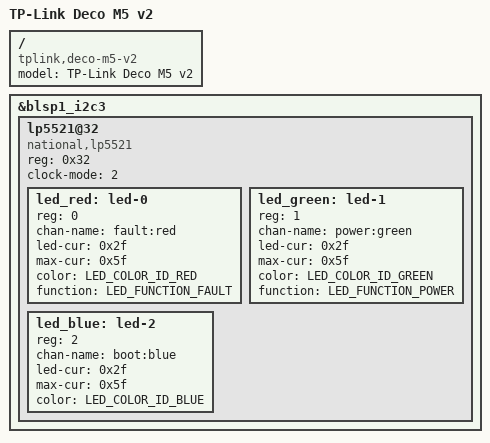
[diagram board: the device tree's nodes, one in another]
// SPDX-License-Identifier: ISC
// Copyright (c) 2015, The Linux Foundation. All rights reserved.
// Copyright (c) 2021, Frank Veltmans <veltmans.frank@gmail.com>

#include "qcom-ipq4019-deco-m5.dtsi"

/ {
	model = "TP-Link Deco M5 v2";
	compatible = "tplink,deco-m5-v2";
};

&blsp1_i2c3 {
	lp5521@32 {
		compatible = "national,lp5521";
		reg = <0x32>;
		clock-mode = /bits/ 8 <2>;

		led_red: led-0 {
			reg = <0>;
			chan-name = "fault:red";
			led-cur = /bits/ 8 <0x2f>;
			max-cur = /bits/ 8 <0x5f>;
			color = <LED_COLOR_ID_RED>;
			function = LED_FUNCTION_FAULT;
		};
		led_green: led-1 {
			reg = <1>;
			chan-name = "power:green";
			led-cur = /bits/ 8 <0x2f>;
			max-cur = /bits/ 8 <0x5f>;
			color = <LED_COLOR_ID_GREEN>;
			function = LED_FUNCTION_POWER;
		};
		led_blue: led-2 {
			reg = <2>;
			chan-name = "boot:blue";
			led-cur = /bits/ 8 <0x2f>;
			max-cur = /bits/ 8 <0x5f>;
			color = <LED_COLOR_ID_BLUE>;
		};
	};
};
